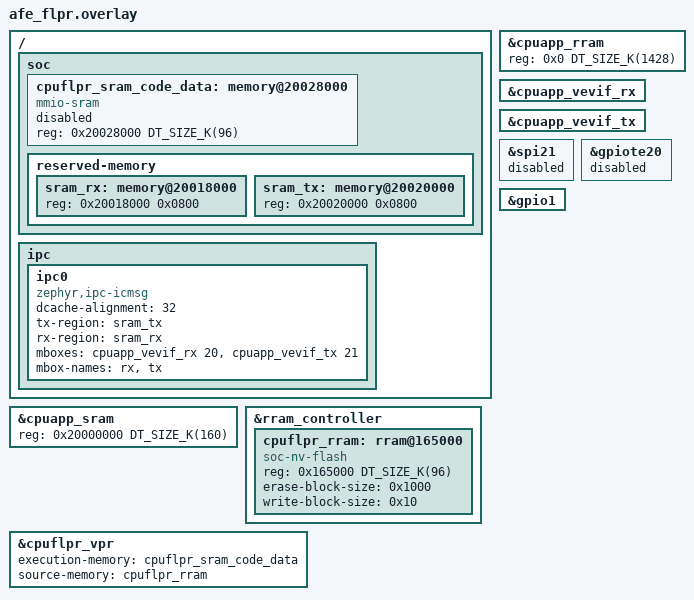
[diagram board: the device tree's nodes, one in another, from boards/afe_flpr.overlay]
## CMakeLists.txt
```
cmake_minimum_required(VERSION 3.20.0)

list(APPEND ZEPHYR_EXTRA_MODULES ${CMAKE_CURRENT_SOURCE_DIR}/../wheeze)

# Where the ADS1292R is read: "flpr" (default) = the RISC-V coprocessor, built
# by sysbuild from flpr/; "app" = an afe thread on this core (no sysbuild needed).
set(AFE_CORE flpr CACHE STRING "Core that reads the ADS1292R: flpr or app")
if(AFE_CORE STREQUAL "flpr")
  list(APPEND EXTRA_DTC_OVERLAY_FILE ${CMAKE_CURRENT_SOURCE_DIR}/boards/afe_flpr.overlay)
elseif(NOT AFE_CORE STREQUAL "app")
  message(FATAL_ERROR "AFE_CORE must be flpr or app")
endif()

find_package(Zephyr REQUIRED HINTS $ENV{ZEPHYR_BASE})
project(anaphylaxis_monitor LANGUAGES C CXX)

target_include_directories(app PRIVATE src)
target_sources(app PRIVATE
  src/main.cpp
  src/afe_link.cpp
  src/burst.cpp
  src/patch_link.cpp
  src/algo/anaphylaxis.cpp
  src/algo/body_motion.cpp
  src/algo/ecg_qrs.cpp
  src/algo/ppg.cpp
  src/algo/resp_rate.cpp
  src/drivers/ads1292r.cpp
  src/drivers/alert.cpp
  src/drivers/lsm6dso.cpp
  src/drivers/max30101.cpp
)
```

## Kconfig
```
# EpiPatch chest patch -- application options.
# All thresholds are PLACEHOLDERS to be set from clinical validation.
# The countdown, release and histamine options live in ../thigh/Kconfig.

menu "EpiPatch chest patch"

config APP_AFE_ON_FLPR
	def_bool $(dt_nodelabel_enabled,cpuflpr_vpr)
	select IPC_SERVICE
	select MBOX
	help
	  The ADS1292R is read by the FLPR coprocessor (flpr/), which runs the
	  heart-rate and breathing triggers and wakes this core only when one
	  fires. Set by the build: on unless CMake is given -DAFE_CORE=app.

config APP_AFE_STACK_SIZE
	int "ECG/Bio-Z thread stack size (AFE on this core only)"
	default 2048

config APP_AFE_THREAD_PRIORITY
	int "ECG/Bio-Z thread priority (must beat main: ADS1292R has no FIFO)"
	default 1

config APP_WATCHDOG_MS
	int "Hardware watchdog timeout [ms]"
	default 4000

menu "Sampling schedule and ECG/Bio-Z triggers"

config APP_SPOT_PERIOD_S
	int "Read all sensors every [s]"
	default 120

config APP_SPOT_WINDOW_S
	int "...for [s] (PPG, mic and histamine on, decision every second)"
	default 15

config APP_BURST_S
	int "After an ECG/Bio-Z trigger, record everything for [s], then analyse"
	range 10 60
	default 60

config APP_TRIG_HR_HIGH_BPM
	int "Heart-rate trigger: at or above [/min]"
	default 110
	help
	  Starts a recording; it is not a finding. Set below the tachycardia
	  finding (APP_HR_HIGH_BPM) so the recording is already running when
	  the finding could form.

config APP_TRIG_HR_LOW_BPM
	int "Heart-rate trigger: at or below [/min]"
	default 40

config APP_TRIG_RR_HIGH_BPM
	int "Breathing trigger: at or above [/min]"
	default 25
	help
	  25/min is where NEWS2 scores breathing rate 3.

config APP_TRIG_RR_LOW_BPM
	int "Breathing trigger: at or below [/min]"
	default 8

config APP_TRIG_APNEA
	bool "Breathing trigger: also on apnea"
	default y

config APP_TRIG_CONFIRM_S
	int "A trigger condition must last [s]"
	default 5

config APP_IMU_FIFO_WTM
	int "IMU FIFO watermark interrupt [samples at 12.5 Hz]"
	range 8 60
	default 32
	help
	  Wakes this core to update posture and collapse detection while the
	  schedule is idle (32 samples = every 2.6 s).

config APP_HIST_PERIOD_S
	int "While reading, ask the thigh patch for fresh histamine every [s]"
	default 10

endmenu

menu "Link to the thigh patch"

config APP_THIGH_FRESH_S
	int "Thigh data counts as missing after [s] without a report"
	default 300
	help
	  Without fresh thigh data the chest has no histamine (no exposure
	  finding) and no thigh fall; it keeps deciding on its own sensors.
	  The thigh reports at least every 2 minutes and on every request.

endmenu

menu "PPG (MAX30101)"

config APP_PPG_RED_PA
	int "Red LED current [0.2 mA steps]"
	range 0 255
	default 36

config APP_PPG_IR_PA
	int "IR LED current [0.2 mA steps]"
	range 0 255
	default 36

endmenu

menu "Chest IMU (LSM6DSO)"

config APP_TAP_ODR_HZ
	int "Accelerometer rate [Hz] (ST recommends >= 417 for taps)"
	default 417

config APP_TAP_THRESHOLD_MG
	int "Tap threshold [mg] (250 mg steps)"
	default 1500

config APP_TAP_COUNT
	int "Taps that cancel a deployment (sent to the thigh patch)"
	range 2 8
	default 3

config APP_TAP_WINDOW_MS
	int "All taps within [ms]"
	default 1500

config APP_IMPACT_MG
	int "Impact (wake-up) threshold [mg] (125 mg steps, max 7875)"
	default 2500

config APP_FREEFALL_MG
	int "Free-fall threshold [mg] (156..500)"
	default 312

config APP_FREEFALL_MS
	int "Free-fall minimum duration [ms]"
	default 60

config APP_CHEST_UP_AXIS
	int "Chest IMU axis pointing to the head when standing (0 +X,1 -X,2 +Y,3 -Y,4 +Z,5 -Z)"
	range 0 5
	default 0

config APP_COLLAPSE_TRANSITION_MS
	int "Collapse: trunk tilt 35 -> 60 deg faster than [ms]"
	default 800
	help
	  A faint crosses this band in ~0.2-0.5 s; lying down on purpose,
	  even briskly, takes about 1 s or more.

config APP_COLLAPSE_STILL_S
	int "Collapse: then motionless for [s]"
	default 15

config APP_FALL_CONFIRM_S
	int "Fall: still lying this long after the impact [s]"
	default 10

config APP_STILL_MG
	int "Motionless / at rest below [mg] of dynamic acceleration"
	default 50

config APP_ACTIVE_MG
	int "Moving above [mg]: ignore heart/breathing-rate findings (exercise)"
	default 150

endmenu

menu "Findings and rules"

config APP_WHEEZE_MIN_S
	int "Wheeze finding: wheeze heard in at least this many seconds..."
	range 1 8
	default 3
	help
	  A single detection is not a finding: the wheeze CNN flags about a
	  quarter of normal breath cycles (0.75 specificity on ICBHI).

config APP_WHEEZE_WINDOW_S
	int "...within this window [s]"
	default 60

config APP_WHEEZE_RECENT_S
	int "Wheeze finding holds for [s] after the repeat rule was last met"
	default 60

config APP_RR_HIGH_BPM
	int "Fast breathing at or above [/min]"
	default 28

config APP_RR_HIGH_HOLD_S
	int "...for [s]"
	default 30

config APP_RR_LOW_BPM
	int "Slow breathing at or below [/min]"
	default 8

config APP_RR_LOW_HOLD_S
	int "...for [s]"
	default 15

config APP_APNEA_S
	int "Apnea: no breath for [s]"
	default 20

config APP_HR_HIGH_BPM
	int "Tachycardia at or above [/min]"
	default 120

config APP_HR_RISE_BPM
	int "...and at least this far above the resting baseline [/min]"
	default 40

config APP_HR_HOLD_S
	int "...for [s]"
	default 60

config APP_PI_DROP_PCT
	int "Perfusion drop: PI at or below this % of baseline"
	default 50

config APP_PI_HOLD_S
	int "...for [s]"
	default 30

config APP_HIST_EXPOSURE_MIN
	int "Elevated histamine (from the thigh) counts as exposure for [min]"
	default 60
	help
	  Plasma histamine peaks 5-10 min after exposure and is back to
	  baseline by 15-60 min (Schwartz 1989), while food reactions reach
	  the airway or circulation in about 30 min (Pumphrey 2000).

config APP_RULE_EXPOSURE
	bool "Rule A: histamine AND (respiratory OR cardiovascular finding)"
	default y

config APP_RULE_RESP_COLLAPSE
	bool "Rule B: respiratory finding AND collapse/fall (no histamine needed)"
	default y

endmenu

module = APP
module-str = app
source "subsys/logging/Kconfig.template.log_config"

endmenu

source "Kconfig.zephyr"
```

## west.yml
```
manifest:
  remotes:
    - name: zephyrproject-rtos
      url-base: https://github.com/zephyrproject-rtos
  projects:
    - name: zephyr
      remote: zephyrproject-rtos
      revision: v4.4.2
      import:
        name-allowlist:
          - cmsis
          - cmsis_6
          - cmsis-dsp
          - cmsis-nn
          - hal_nordic
          - segger
          - mbedtls
          - tf-psa-crypto
  self:
    path: manifest
```

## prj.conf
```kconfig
# EpiPatch chest patch. Battery build: no UART, no logging.
# Use debug.conf for logs over RTT.

CONFIG_CPP=y
CONFIG_STD_CPP20=y
CONFIG_REQUIRES_FULL_LIBCPP=y
CONFIG_FPU=y
CONFIG_FPU_SHARING=y

# microphone wheeze detector (../wheeze module)
CONFIG_WHEEZE_DETECTOR=y

# vital-sign filters (biquads on the FPU)
CONFIG_CMSIS_DSP=y
CONFIG_CMSIS_DSP_FILTERING=y

CONFIG_GPIO=y
CONFIG_SPI=y
CONFIG_I2C=y
CONFIG_WATCHDOG=y
CONFIG_EVENTS=y
# own register-level drivers; keep Zephyr's sensor drivers out
CONFIG_SENSOR=n

CONFIG_MAIN_STACK_SIZE=4096
CONFIG_MAIN_THREAD_PRIORITY=4
CONFIG_PM_DEVICE=y

# Bluetooth LE link to the thigh patch: central + GATT client, one bonded
# peer, LE Secure Connections only, bond kept in RRAM
CONFIG_BT=y
CONFIG_BT_CENTRAL=y
CONFIG_BT_GATT_CLIENT=y
CONFIG_BT_GATT_AUTO_DISCOVER_CCC=y
CONFIG_BT_SMP=y
CONFIG_BT_SMP_SC_ONLY=y
CONFIG_BT_SMP_APP_PAIRING_ACCEPT=y
CONFIG_BT_BONDABLE=y
CONFIG_BT_MAX_CONN=1
CONFIG_BT_MAX_PAIRED=1
CONFIG_BT_SETTINGS=y
CONFIG_BT_DEVICE_NAME="EpiPatch-C"

# Bluetooth bond in RRAM
CONFIG_FLASH=y
CONFIG_FLASH_MAP=y
CONFIG_ZMS=y
CONFIG_SETTINGS=y
CONFIG_SETTINGS_ZMS=y

CONFIG_SERIAL=n
CONFIG_CONSOLE=n
CONFIG_UART_CONSOLE=n
CONFIG_LOG=n
CONFIG_PRINTK=n
CONFIG_BOOT_BANNER=n

# The mic listens only when the sampling schedule asks (wheeze_listen()) or
# while a wheeze is going on; its own duty cycle is effectively off.
CONFIG_WHEEZE_DUTY_SLEEP_MS=3600000
```

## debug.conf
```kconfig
# west build ... -- -DEXTRA_CONF_FILE=debug.conf
# Logs over UART. The overlay's pin map uses the DK's VCOM pins, so for logs
# switch to RTT instead (CONFIG_USE_SEGGER_RTT + CONFIG_LOG_BACKEND_RTT) or remap.
CONFIG_SERIAL=y
CONFIG_CONSOLE=y
CONFIG_LOG=y
CONFIG_PRINTK=y
CONFIG_USE_SEGGER_RTT=y
CONFIG_LOG_BACKEND_RTT=y
CONFIG_LOG_BACKEND_UART=n
CONFIG_UART_CONSOLE=n
CONFIG_RTT_CONSOLE=y
CONFIG_APP_LOG_LEVEL_INF=y
CONFIG_WHEEZE_PROFILING=y
```

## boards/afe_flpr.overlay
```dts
/*
 * The ADS1292R belongs to the FLPR coprocessor (firmware in ../flpr, built by
 * sysbuild): the application core gives up SPI21 and GPIOTE20 (DRDY is on
 * port 1), launches the coprocessor and talks to it over one ICMsg endpoint.
 * Memory layout as in Zephyr's nordic-flpr snippet: the coprocessor runs from
 * the top 96 kB of RAM, so the application core keeps 160 kB.
 */

/ {
	soc {
		cpuflpr_sram_code_data: memory@20028000 {
			compatible = "mmio-sram";
			reg = <0x20028000 DT_SIZE_K(96)>;
			ranges = <0x0 0x20028000 0x18000>;
			status = "reserved";
			#address-cells = <1>;
			#size-cells = <1>;
		};

		reserved-memory {
			#address-cells = <1>;
			#size-cells = <1>;

			sram_rx: memory@20018000 {
				reg = <0x20018000 0x0800>;
			};

			sram_tx: memory@20020000 {
				reg = <0x20020000 0x0800>;
			};
		};
	};

	ipc {
		ipc0: ipc0 {
			compatible = "zephyr,ipc-icmsg";
			dcache-alignment = <32>;
			tx-region = <&sram_tx>;
			rx-region = <&sram_rx>;
			mboxes = <&cpuapp_vevif_rx 20>, <&cpuapp_vevif_tx 21>;
			mbox-names = "rx", "tx";
			status = "okay";
		};
	};
};

&cpuapp_sram {
	reg = <0x20000000 DT_SIZE_K(160)>;
	ranges = <0x0 0x20000000 0x28000>;
};

&cpuapp_rram {
	reg = <0x0 DT_SIZE_K(1428)>;
	ranges = <0x0 0x0 DT_SIZE_K(1428)>;

	/delete-node/ partitions;
};

&rram_controller {
	cpuflpr_rram: rram@165000 {
		compatible = "soc-nv-flash";
		reg = <0x165000 DT_SIZE_K(96)>;
		ranges = <0x0 0x165000 DT_SIZE_K(96)>;
		erase-block-size = <0x1000>;
		write-block-size = <0x10>;
		#address-cells = <1>;
		#size-cells = <1>;
	};
};

&cpuflpr_vpr {
	status = "okay";
	execution-memory = <&cpuflpr_sram_code_data>;
	source-memory = <&cpuflpr_rram>;
};

&cpuapp_vevif_rx {
	status = "okay";
};

&cpuapp_vevif_tx {
	status = "okay";
};

&spi21 {
	status = "disabled";
};

&gpiote20 {
	status = "disabled";
};

/* port 1 pins stay usable here as outputs (motor gate, buzzer), no interrupts */
&gpio1 {
	/delete-property/ gpiote-instance;
};

#define WITH_FLPR_PARTITIONS
#include <vendor/nordic/nrf54l15_cpuapp_partition.dtsi>
```

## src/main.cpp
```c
// EpiPatch chest patch, nRF54L15: senses, analyses and decides.
//
// Who does what
//   FLPR    (low-power RISC-V core, flpr/) ADS1292R at 125 Hz -> heart rate,
//           breathing rate and the two vital-sign triggers. It wakes the main
//           core only when a trigger fires. (With -DAFE_CORE=app an afe thread
//           on the main core does the same; see afe_link.cpp.)
//   main    (Arm Cortex-M33, prio 4) event loop: chest IMU interrupts at any
//           time (tap / impact / free-fall / FIFO watermark), the sampling
//           schedule, the analysis and the decision
//   wheeze  (prio 5) PDM mic -> wheeze CNN (wheeze module), listening when asked
//   BT      Bluetooth LE link to the thigh patch (patch_link.cpp)
//
// The thigh patch (../thigh) owns the histamine sensor, its own fall
// detection, the vibration motor and the release motor. It reports its data
// here; the chest folds it into the decision and sends the verdict back. The
// thigh then runs the countdown, the tap cancel and the release itself.
//
// Sampling schedule (algo/sampling_schedule.hpp)
//   every 2 min      spot read: PPG, mic and thigh histamine for 15 s, decision every second
//   ECG/Bio-Z trigger burst: everything on for 1 min, every sample kept, then
//                    the whole minute is analysed (burst.hpp)
//   countdown on     everything on, decision every second, until it is over
#include <algorithm>
#include <array>
#include <atomic>
#include <cstdint>
#include <span>

#include <zephyr/drivers/watchdog.h>
#include <zephyr/kernel.h>
#include <zephyr/logging/log.h>
#include <zephyr/spinlock.h>

#include <wheeze/wheeze.h>

#include "afe_link.hpp"
#include "algo/anaphylaxis.hpp"
#include "algo/body_motion.hpp"
#include "algo/ppg.hpp"
#include "algo/sampling_schedule.hpp"
#include "algo/tap_counter.hpp"
#include "algo/thigh_view.hpp"
#include "algo/vital_trigger.hpp"
#include "board.hpp"
#include "burst.hpp"
#include "drivers/alert.hpp"
#include "drivers/lsm6dso.hpp"
#include "drivers/max30101.hpp"
#include "patch_link.hpp"

LOG_MODULE_REGISTER(device, CONFIG_APP_LOG_LEVEL);

namespace {

using namespace dev;
using algo::DeployState;
using algo::SamplingSchedule;
using afe_msg::StreamMode;

// ---- events into the main loop ---------------------------------------------

enum : uint32_t {
	kEvPpg = BIT(0),
	kEvChest = BIT(1),
	kEvTrigger = BIT(2),
	kEvReport = BIT(3),
	kEvAll = kEvPpg | kEvChest | kEvTrigger | kEvReport,
};

k_event g_events;

void post(void *bit) { k_event_post(&g_events, static_cast<uint32_t>(reinterpret_cast<uintptr_t>(bit))); }

void *ev_arg(uint32_t bit) { return reinterpret_cast<void *>(static_cast<uintptr_t>(bit)); }

// ---- hardware ----------------------------------------------------------------

// constinit: the compiler guarantees no constructor runs at boot
constinit drv::Max30101 ppg{board::kPpgI2c, board::kPpgInt};
constinit drv::Lsm6dso imu_chest{board::kChestI2c, board::kChestInt};
constinit drv::Alert alert{board::kAlert, board::kStatusLed};

// ---- algorithms --------------------------------------------------------------

// value-initialised ({}), so they are zero-filled at link time instead of
// constructed at boot; each is configured by reset() in configure_algorithms()
constinit algo::PpgProcessor ppg_proc{};
constinit algo::BodyMotion motion{};
constinit algo::TapCounter taps{};
constinit algo::AnaphylaxisEngine engine{};
constinit SamplingSchedule schedule{};
constinit algo::ThighView thigh{};

std::atomic<uint8_t> pending_trigger{0}; // VitalTrigger bits, set by the AFE side

// latest thigh report, written by the Bluetooth thread
constinit k_spinlock report_lock{};
constinit patch_msg::Report pending_report{};
bool report_waiting;

bool ok_ppg, ok_chest;
bool ppg_on;
uint32_t last_ppg_ms, next_hist_ms;
DeployState shown_state = DeployState::Monitoring;

// ---- configuration from Kconfig ----------------------------------------------

algo::Axis axis(int v) { return static_cast<algo::Axis>(std::clamp(v, 0, 5)); }

algo::VitalTrigger::Config trigger_config()
{
	return {
		.hr_high = static_cast<float>(CONFIG_APP_TRIG_HR_HIGH_BPM),
		.hr_low = static_cast<float>(CONFIG_APP_TRIG_HR_LOW_BPM),
		.rr_high = static_cast<float>(CONFIG_APP_TRIG_RR_HIGH_BPM),
		.rr_low = static_cast<float>(CONFIG_APP_TRIG_RR_LOW_BPM),
		.apnea = IS_ENABLED(CONFIG_APP_TRIG_APNEA),
		.confirm_ms = CONFIG_APP_TRIG_CONFIRM_S * 1000u,
	};
}

void configure_algorithms()
{
	ppg_proc.reset({});
	motion.reset({
		.chest_up = axis(CONFIG_APP_CHEST_UP_AXIS),
		.collapse_transition_ms = CONFIG_APP_COLLAPSE_TRANSITION_MS,
		.collapse_still_ms = CONFIG_APP_COLLAPSE_STILL_S * 1000u,
		.fall_confirm_ms = CONFIG_APP_FALL_CONFIRM_S * 1000u,
		.still_g = CONFIG_APP_STILL_MG / 1000.0f,
	});
	taps.reset({.taps = CONFIG_APP_TAP_COUNT, .window_ms = CONFIG_APP_TAP_WINDOW_MS});
	engine.reset({
		.active_g = CONFIG_APP_ACTIVE_MG / 1000.0f,
		.rest_g = CONFIG_APP_STILL_MG / 1000.0f,
		.wheeze_min_s = CONFIG_APP_WHEEZE_MIN_S,
		.wheeze_window_ms = CONFIG_APP_WHEEZE_WINDOW_S * 1000u,
		.wheeze_recent_ms = CONFIG_APP_WHEEZE_RECENT_S * 1000u,
		.rr_high_bpm = static_cast<float>(CONFIG_APP_RR_HIGH_BPM),
		.rr_high_hold_ms = CONFIG_APP_RR_HIGH_HOLD_S * 1000u,
		.rr_low_bpm = static_cast<float>(CONFIG_APP_RR_LOW_BPM),
		.rr_low_hold_ms = CONFIG_APP_RR_LOW_HOLD_S * 1000u,
		.hr_high_bpm = static_cast<float>(CONFIG_APP_HR_HIGH_BPM),
		.hr_rise_bpm = static_cast<float>(CONFIG_APP_HR_RISE_BPM),
		.hr_hold_ms = CONFIG_APP_HR_HOLD_S * 1000u,
		.pi_drop_ratio = CONFIG_APP_PI_DROP_PCT / 100.0f,
		.pi_hold_ms = CONFIG_APP_PI_HOLD_S * 1000u,
		.exposure_hold_ms = CONFIG_APP_HIST_EXPOSURE_MIN * 60000u,
		.rule_exposure = IS_ENABLED(CONFIG_APP_RULE_EXPOSURE),
		.rule_resp_collapse = IS_ENABLED(CONFIG_APP_RULE_RESP_COLLAPSE),
	});
	thigh.reset({.fresh_ms = CONFIG_APP_THIGH_FRESH_S * 1000u});
}

// ---- callbacks (other threads / ISRs) ------------------------------------------

void on_trigger(uint8_t bits)
{
	pending_trigger.fetch_or(bits);
	k_event_post(&g_events, kEvTrigger);
}

void on_report(const patch_msg::Report &r)
{
	const k_spinlock_key_t key = k_spin_lock(&report_lock);
	pending_report = r;
	report_waiting = true;
	k_spin_unlock(&report_lock, key);
	k_event_post(&g_events, kEvReport);
}

// ---- main-loop handlers ----------------------------------------------------------

// the chest's buzzer/LED follow the thigh's countdown
void mirror_thigh_state(DeployState s)
{
	if (s == shown_state) {
		return;
	}
	shown_state = s;
	switch (s) {
	case DeployState::Alert:
		alert.play(drv::Alert::kCountdown, true);
		LOG_WRN("thigh patch: countdown running");
		break;
	case DeployState::Cancelled:
		alert.play(drv::Alert::kCancelAck, true);
		LOG_WRN("thigh patch: cancelled");
		break;
	case DeployState::Deploying:
		LOG_WRN("thigh patch: releasing");
		break;
	case DeployState::Deployed:
		alert.play(drv::Alert::kDeployed, false);
		LOG_WRN("thigh patch: deployed");
		break;
	case DeployState::Fault:
		alert.play(drv::Alert::kFault, true);
		LOG_ERR("thigh patch: release motor fault");
		break;
	case DeployState::Monitoring:
		alert.play(drv::Alert::kOff, false);
		break;
	}
}

void apply_report(uint32_t now)
{
	patch_msg::Report r;
	{
		const k_spinlock_key_t key = k_spin_lock(&report_lock);
		if (!report_waiting) {
			k_spin_unlock(&report_lock, key);
			return;
		}
		r = pending_report;
		report_waiting = false;
		k_spin_unlock(&report_lock, key);
	}
	thigh.on_report(r, now);
	mirror_thigh_state(thigh.state());
}

bool alerting(uint32_t now) { return thigh.alerting(now); }

// the verdict goes to the thigh, which runs the countdown and release
void decide(const algo::Assessment &a)
{
	link::send_decision(a);
	if (a.trigger) {
		LOG_WRN("DECISION: findings 0x%03x%s -> thigh patch", a.findings, a.severe ? " (severe)" : "");
	}
}

void read_imu_fifo(uint32_t now)
{
	std::array<algo::Vec3, drv::Lsm6dso::kMaxFifo> buf;
	const int n = imu_chest.read_fifo(buf);
	if (n <= 0) {
		return;
	}
	const auto s = std::span(buf).first(static_cast<std::size_t>(n));
	// posture and collapse always run live, so they work between scheduled reads
	motion.chest(s, now, drv::Lsm6dso::kFifoDtMs);
	if (schedule.mode() == SamplingSchedule::Mode::Burst) {
		burst::add_imu(true, s);
	}
}

void handle_imu(uint32_t now)
{
	for (int i = 0; i < 4; ++i) {
		const int ev = imu_chest.events();
		if (ev < 0) {
			return;
		}
		if ((ev & drv::Lsm6dso::kTap) && taps.on_tap(now)) {
			link::send_cancel(); // the thigh runs the countdown
			LOG_WRN("cancel tapped on the chest");
		}
		if (ev & drv::Lsm6dso::kImpact) {
			motion.impact(now);
		}
		if (ev & drv::Lsm6dso::kFreeFall) {
			motion.freefall(now);
		}
		if (ev & drv::Lsm6dso::kFifo) {
			read_imu_fifo(now);
		}
		if (!imu_chest.irq_active()) {
			return;
		}
	}
}

void read_ppg(uint32_t now)
{
	std::array<uint32_t, drv::Max30101::kFifoDepth> red, ir;
	const int n = ppg.read(red, ir);
	if (n > 0) {
		const auto cnt = static_cast<std::size_t>(n);
		const auto r = std::span(red).first(cnt);
		const auto i = std::span(ir).first(cnt);
		if (schedule.mode() == SamplingSchedule::Mode::Burst) {
			burst::add_ppg(r, i); // analysed at the end of the minute
		} else {
			ppg_proc.process(r, i);
		}
	}
	last_ppg_ms = now;
}

// histamine is measured on the thigh: ask for a fresh reading
void request_histamine(uint32_t now)
{
	link::request_report();
	next_hist_ms = now + CONFIG_APP_HIST_PERIOD_S * 1000u;
}

// PPG and mic on for listen_ms (0 = until sensors_off(), renewed by tick)
void sensors_on(uint32_t now, uint32_t listen_ms)
{
	if (ok_ppg && !ppg_on) {
		ppg_on = ppg.wake() == 0;
		ppg_proc.reset({});
		last_ppg_ms = now;
	}
	wheeze_listen(listen_ms ? listen_ms : 3000);
	request_histamine(now);
}

void sensors_off()
{
	if (ppg_on) {
		ppg.shutdown();
		ppg_on = false;
	}
	afe::stream(StreamMode::Off);
}

Vitals snapshot(uint32_t now)
{
	const afe::Reading r = afe::latest();
	const bool afe_fresh = r.updated_ms != 0 && now - r.updated_ms < 2000;

	wheeze_stats ws{};
	wheeze_get_stats(&ws);

	Vitals v{};
	v.hr_valid = afe_fresh && r.hr_valid;
	v.hr_bpm = r.hr_bpm;
	v.ecg_leads_off = r.leads_off;
	v.rr_valid = afe_fresh && r.rr_valid;
	v.rr_bpm = r.rr_bpm;
	v.apnea = afe_fresh && r.apnea;
	v.ppg_valid = ppg_on && ppg_proc.valid();
	v.pi_pct = ppg_proc.pi_pct();
	v.pulse_bpm = ppg_proc.pulse_bpm();
	v.spo2_est = ppg_proc.spo2_est();
	v.wheezing = ws.wheezing;
	v.wheeze_events = ws.events;
	v.posture = motion.posture();
	v.activity_g = motion.activity_g();
	v.collapsed = motion.collapsed();
	v.fall = motion.fall();
	thigh.merge(v, now); // histamine, thigh fall and activity
	return v;
}

void log_vitals(const Vitals &v, uint16_t findings)
{
	LOG_INF("HR %s%d RR %s%d PI %d.%02d%% post %d act %dmg hist %s%d/%d nM wz %d find 0x%03x "
		"thigh %d mode %d",
		v.hr_valid ? "" : "~", static_cast<int>(v.hr_bpm), v.rr_valid ? "" : "~",
		static_cast<int>(v.rr_bpm), static_cast<int>(v.pi_pct), static_cast<int>(v.pi_pct * 100) % 100,
		static_cast<int>(v.posture), static_cast<int>(v.activity_g * 1000), v.hist_valid ? "" : "~",
		static_cast<int>(v.hist_nm), static_cast<int>(v.hist_baseline_nm), v.wheezing, findings,
		static_cast<int>(shown_state), static_cast<int>(schedule.mode()));
}

// once a second while the schedule is awake (spot, burst or countdown)
void tick(uint32_t now)
{
	if (ok_chest) {
		read_imu_fifo(now);
	}
	if (ppg_on && now - last_ppg_ms > 2000) {
		read_ppg(now); // missed interrupt: poll
	}
	if (static_cast<int32_t>(now - next_hist_ms) >= 0) {
		request_histamine(now);
	}
	motion.update(now);
	const Vitals v = snapshot(now);

	if (schedule.mode() == SamplingSchedule::Mode::Burst) {
		burst::add_second(v, now); // decided at the end of the minute
		return;
	}
	if (schedule.mode() == SamplingSchedule::Mode::Active) {
		wheeze_listen(3000); // keep the mic on until the countdown is over
	}
	const algo::Assessment a = engine.update(v, now);
	decide(a);

	static uint32_t log_div;
	if (++log_div >= 5) {
		log_div = 0;
		log_vitals(v, a.findings);
	}
}

void end_burst()
{
	const burst::Info info = burst::info();
	const algo::Assessment a = burst::analyse(engine, ppg_proc);
	const afe::Recording rec = afe::recording();
	LOG_INF("burst analysed: %u s, %u PPG, %u IMU, %u ECG/Bio-Z samples; findings 0x%03x%s",
		static_cast<unsigned>(info.seconds), static_cast<unsigned>(info.ppg_samples),
		static_cast<unsigned>(info.chest_samples), static_cast<unsigned>(rec.samples), a.findings,
		a.trigger ? " -> TRIGGER" : "");
	decide(a);
	afe::rearm();
}

void handle_schedule(SamplingSchedule::Action act, uint32_t now)
{
	using A = SamplingSchedule::Action;
	switch (act) {
	case A::StartSpot:
		sensors_on(now, CONFIG_APP_SPOT_WINDOW_S * 1000u);
		afe::stream(StreamMode::Status);
		break;
	case A::StartBurst:
		burst::begin(now);
		sensors_on(now, CONFIG_APP_BURST_S * 1000u);
		afe::stream(StreamMode::Record);
		break;
	case A::StartActive:
		sensors_on(now, 0);
		afe::stream(StreamMode::Status);
		break;
	case A::EndSpot:
		sensors_off();
		break;
	case A::EndActive:
		sensors_off();
		afe::rearm();
		break;
	case A::EndBurst:
		sensors_off();
		end_burst();
		break;
	case A::None:
		break;
	}
}

// ---- boot helpers ------------------------------------------------------------------

struct Watchdog {
	const device *dev = nullptr;
	int channel = -1;

	void start()
	{
#if DT_NODE_HAS_STATUS(DT_ALIAS(watchdog0), okay)
		dev = DEVICE_DT_GET(DT_ALIAS(watchdog0));
		if (!device_is_ready(dev)) {
			dev = nullptr;
			return;
		}
		wdt_timeout_cfg cfg{};
		cfg.window.min = 0;
		cfg.window.max = CONFIG_APP_WATCHDOG_MS;
		cfg.flags = WDT_FLAG_RESET_SOC;
		channel = wdt_install_timeout(dev, &cfg);
		if (channel < 0 || wdt_setup(dev, WDT_OPT_PAUSE_HALTED_BY_DBG) != 0) {
			dev = nullptr;
		}
#endif
	}
	void feed()
	{
		if (dev) {
			wdt_feed(dev, channel);
		}
	}
};

drv::Lsm6dso::Config imu_config()
{
	return {
		.odr_hz = static_cast<uint16_t>(CONFIG_APP_TAP_ODR_HZ),
		.low_power = false,
		.tap = true,
		.tap_mg = CONFIG_APP_TAP_THRESHOLD_MG,
		.impact_mg = CONFIG_APP_IMPACT_MG,
		.freefall_mg = CONFIG_APP_FREEFALL_MG,
		.freefall_ms = CONFIG_APP_FREEFALL_MS,
		.fifo_wtm = CONFIG_APP_IMU_FIFO_WTM,
	};
}

} // namespace

int main()
{
	k_event_init(&g_events);
	alert.init();
	configure_algorithms();

	const int afe_err = afe::start(trigger_config(), CONFIG_APP_APNEA_S * 1000u, on_trigger);
	ok_ppg = ppg.init(CONFIG_APP_PPG_RED_PA, CONFIG_APP_PPG_IR_PA, post, ev_arg(kEvPpg)) == 0;
	if (ok_ppg) {
		ppg.shutdown(); // until the first scheduled read
	}
	ok_chest = imu_chest.init(imu_config(), post, ev_arg(kEvChest)) == 0;
	const int bt_err = link::start(on_report);
	LOG_INF("chest: ecg/bioz %d (%s) ppg %d imu %d bluetooth %d", afe_err == 0,
		IS_ENABLED(CONFIG_APP_AFE_ON_FLPR) ? "FLPR" : "app core", ok_ppg, ok_chest, bt_err == 0);

	const int werr = wheeze_start(nullptr, nullptr);
	if (werr) {
		LOG_ERR("wheeze detector not started (%d)", werr);
	}

	Watchdog wdt;
	wdt.start();

	uint32_t now = k_uptime_get_32();
	schedule.reset(
		{
			.period_ms = CONFIG_APP_SPOT_PERIOD_S * 1000u,
			.spot_ms = CONFIG_APP_SPOT_WINDOW_S * 1000u,
			.burst_ms = CONFIG_APP_BURST_S * 1000u,
		},
		now);
	next_hist_ms = now;
	uint32_t next_tick = now + 1000;

	for (;;) {
		// sleep until an interrupt, the next tick (when awake) or the next
		// scheduled read (when idle); wake at least twice per watchdog period
		now = k_uptime_get_32();
		uint32_t wait = CONFIG_APP_WATCHDOG_MS / 2;
		if (schedule.awake()) {
			const auto to_tick = static_cast<int32_t>(next_tick - now);
			wait = std::min<uint32_t>(wait, to_tick > 0 ? static_cast<uint32_t>(to_tick) : 0);
		} else {
			wait = std::min(wait, schedule.idle_wait_ms(now));
		}
		const uint32_t ev = k_event_wait(&g_events, kEvAll, false, K_MSEC(wait));
		k_event_clear(&g_events, ev);
		now = k_uptime_get_32();

		if (ev & kEvChest) {
			handle_imu(now);
		}
		if ((ev & kEvPpg) && ppg_on) {
			read_ppg(now);
		}
		if (ev & kEvReport) {
			apply_report(now);
		}
		if (ev & kEvTrigger) {
			const uint8_t bits = pending_trigger.exchange(0);
			const auto act = schedule.trigger(now);
			LOG_INF("ECG/Bio-Z trigger 0x%02x%s", bits,
				act == SamplingSchedule::Action::StartBurst ? ": recording 1 min" : "");
			// otherwise a burst or a countdown already has everything on; the
			// trigger is re-armed when that ends
			if (act == SamplingSchedule::Action::StartBurst) {
				handle_schedule(act, now);
				next_tick = now + 1000;
			}
		}

		const bool was_awake = schedule.awake();
		for (auto act = schedule.update(now, alerting(now)); act != SamplingSchedule::Action::None;
		     act = schedule.update(now, alerting(now))) {
			handle_schedule(act, now);
		}
		if (schedule.awake()) {
			if (!was_awake) {
				next_tick = now + 1000;
			}
			if (static_cast<int32_t>(now - next_tick) >= 0) {
				tick(now);
				next_tick += 1000;
				if (static_cast<int32_t>(now - next_tick) >= 0) {
					next_tick = now + 1000; // fell behind; don't burst
				}
			}
		}
		wdt.feed();
	}
	return 0;
}
```

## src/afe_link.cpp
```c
#include "afe_link.hpp"

#include <array>
#include <atomic>
#include <cstring>

#include <zephyr/kernel.h>
#include <zephyr/logging/log.h>
#include <zephyr/spinlock.h>

#if defined(CONFIG_APP_AFE_ON_FLPR)
#include <zephyr/ipc/ipc_service.h>
#else
#include "algo/ecg_qrs.hpp"
#include "algo/resp_rate.hpp"
#include "board.hpp"
#include "drivers/ads1292r.hpp"
#endif

LOG_MODULE_REGISTER(afe, CONFIG_APP_LOG_LEVEL);

namespace dev::afe {
namespace {

namespace msg = dev::afe_msg;

constinit k_spinlock lock{};
constinit Reading last{};
constinit Recording rec{};
TriggerFn on_trigger_fn;

void publish(const Reading &r)
{
	const k_spinlock_key_t key = k_spin_lock(&lock);
	last = r;
	k_spin_unlock(&lock, key);
}

} // namespace

Reading latest()
{
	const k_spinlock_key_t key = k_spin_lock(&lock);
	const Reading r = last;
	k_spin_unlock(&lock, key);
	return r;
}

Recording recording()
{
	const k_spinlock_key_t key = k_spin_lock(&lock);
	const Recording r = rec;
	k_spin_unlock(&lock, key);
	return r;
}

#if defined(CONFIG_APP_AFE_ON_FLPR)

// ---- the FLPR coprocessor reads the ADS1292R; we talk to it over IPC ----------

namespace {

ipc_ept ep;
std::atomic<bool> bound{false};
msg::Config config_msg;
k_work send_config_work;

void send_config(k_work *) { ipc_service_send(&ep, &config_msg, sizeof(config_msg)); }

void on_bound(void *)
{
	bound = true;
	k_work_submit(&send_config_work); // not from inside the IPC callback
	LOG_INF("AFE coprocessor linked");
}

void on_received(const void *data, size_t len, void *)
{
	if (len < 1) {
		return;
	}
	switch (static_cast<msg::Type>(*static_cast<const uint8_t *>(data))) {
	case msg::Type::Trigger:
		if (len == sizeof(msg::Trigger) && on_trigger_fn) {
			on_trigger_fn(static_cast<const msg::Trigger *>(data)->bits);
		}
		break;
	case msg::Type::Status:
		if (len == sizeof(msg::Status)) {
			const auto *s = static_cast<const msg::Status *>(data);
			publish({
				.hr_valid = (s->flags & msg::kHrValid) != 0,
				.hr_bpm = s->hr_bpm,
				.leads_off = (s->flags & msg::kLeadsOff) != 0,
				.rr_valid = (s->flags & msg::kRrValid) != 0,
				.rr_bpm = s->rr_bpm,
				.apnea = (s->flags & msg::kApnea) != 0,
				.updated_ms = k_uptime_get_32(),
			});
		}
		break;
	case msg::Type::Recording:
		if (len == sizeof(msg::Recording)) {
			const auto *r = static_cast<const msg::Recording *>(data);
			const k_spinlock_key_t key = k_spin_lock(&lock);
			// the coprocessor's RAM is part of the same address space
			rec = {reinterpret_cast<const uint8_t *>(static_cast<uintptr_t>(r->addr)), r->samples,
			       r->sps};
			k_spin_unlock(&lock, key);
		}
		break;
	default:
		break;
	}
}

template <typename T> void send(const T &m)
{
	if (bound) {
		ipc_service_send(&ep, &m, sizeof(m));
	}
}

} // namespace

int start(const algo::VitalTrigger::Config &trig, uint32_t apnea_ms, TriggerFn on_trigger)
{
	on_trigger_fn = on_trigger;
	config_msg = {
		.type = msg::Type::Config,
		.trig_apnea = trig.apnea,
		.reserved = {},
		.hr_high = trig.hr_high,
		.hr_low = trig.hr_low,
		.rr_high = trig.rr_high,
		.rr_low = trig.rr_low,
		.confirm_ms = trig.confirm_ms,
		.apnea_ms = apnea_ms,
	};
	k_work_init(&send_config_work, send_config);

	static const ipc_ept_cfg cfg = {
		.name = "afe",
		.cb = {.bound = on_bound, .received = on_received},
	};
	const device *ipc = DEVICE_DT_GET(DT_NODELABEL(ipc0));
	int err = ipc_service_open_instance(ipc);
	if (err && err != -EALREADY) {
		return err;
	}
	return ipc_service_register_endpoint(ipc, &ep, &cfg);
}

void stream(msg::StreamMode mode) { send(msg::Stream{.type = msg::Type::Stream, .mode = mode}); }

void rearm() { send(msg::Rearm{.type = msg::Type::Rearm}); }

#else

// ---- the ADS1292R is read on this core, by the afe thread ---------------------

namespace {

constinit drv::Ads1292r ads{board::kAdsSpi, board::kAdsDrdy, board::kAdsPwdn, board::kAdsStart};
constinit algo::QrsDetector qrs{};
constinit algo::RespRate resp{};
constinit algo::VitalTrigger trig{};

constexpr std::size_t kRecordSamples = CONFIG_APP_BURST_S * drv::Ads1292r::kSps;
constinit uint8_t record_buf[kRecordSamples * 6]{};
std::atomic<uint8_t> mode{static_cast<uint8_t>(msg::StreamMode::Off)};
std::atomic<bool> rearm_pending{false};

K_THREAD_STACK_DEFINE(afe_stack, CONFIG_APP_AFE_STACK_SIZE);
k_thread afe_thread;

void put24(uint8_t *p, int32_t v)
{
	p[0] = static_cast<uint8_t>(v >> 16);
	p[1] = static_cast<uint8_t>(v >> 8);
	p[2] = static_cast<uint8_t>(v);
}

void afe_loop(void *, void *, void *)
{
	constexpr std::size_t kBlock = drv::Ads1292r::kSps / 5; // 200 ms
	std::array<float, kBlock> ecg, bioz;
	std::size_t n = 0, blocks = 0, rec_n = 0;
	uint8_t loff = 0;
	int misses = 0;
	auto last_mode = msg::StreamMode::Off;

	for (;;) {
		if (ads.wait(K_MSEC(100)) != 0) {
			if (++misses >= 10) {
				// no DRDY for a second: restart the AFE
				LOG_WRN("ADS1292R stalled, re-initialising");
				ads.init();
				misses = 0;
			}
			continue;
		}
		misses = 0;
		drv::Ads1292r::Sample s;
		if (ads.read(s) != 0) {
			continue;
		}

		const auto m = static_cast<msg::StreamMode>(mode.load());
		if (m == msg::StreamMode::Record && last_mode != msg::StreamMode::Record) {
			rec_n = 0;
		}
		if (m == msg::StreamMode::Record && rec_n < kRecordSamples) {
			put24(&record_buf[rec_n * 6], s.ecg);
			put24(&record_buf[rec_n * 6 + 3], s.resp);
			if (++rec_n == kRecordSamples) {
				const k_spinlock_key_t key = k_spin_lock(&lock);
				rec = {record_buf, static_cast<uint32_t>(rec_n), drv::Ads1292r::kSps};
				k_spin_unlock(&lock, key);
			}
		}
		last_mode = m;

		ecg[n] = s.ecg * drv::Ads1292r::kEcgUvPerLsb;
		bioz[n] = static_cast<float>(s.resp);
		loff |= s.loff;
		if (++n < kBlock) {
			continue;
		}
		n = 0;
		// breathing is measured through the same two electrodes as the ECG
		const bool off = loff & (drv::Ads1292r::kLoffEcg | drv::Ads1292r::kLoffResp);
		loff = 0;
		qrs.process(ecg, off);
		resp.process(bioz, off);
		const Reading r{
			.hr_valid = qrs.hr_valid(),
			.hr_bpm = qrs.hr_bpm(),
			.leads_off = off,
			.rr_valid = resp.valid(),
			.rr_bpm = resp.rate_bpm(),
			.apnea = resp.apnea(),
			.updated_ms = k_uptime_get_32(),
		};
		publish(r);
		if (++blocks < 5) {
			continue;
		}
		blocks = 0;

		// ---- once a second: the triggers ----
		if (rearm_pending.exchange(false)) {
			trig.rearm();
		}
		const uint8_t fired = trig.update(
			{
				.hr_valid = r.hr_valid,
				.hr_bpm = r.hr_bpm,
				.rr_valid = r.rr_valid,
				.rr_bpm = r.rr_bpm,
				.apnea = r.apnea,
				.leads_off = off,
			},
			r.updated_ms);
		if (fired && on_trigger_fn) {
			on_trigger_fn(fired);
		}
	}
}

} // namespace

int start(const algo::VitalTrigger::Config &cfg, uint32_t apnea_ms, TriggerFn on_trigger)
{
	on_trigger_fn = on_trigger;
	qrs.reset();
	resp.reset({.apnea_ms = apnea_ms});
	trig.reset(cfg);
	const int err = ads.init();
	if (err) {
		return err;
	}
	k_thread_create(&afe_thread, afe_stack, K_THREAD_STACK_SIZEOF(afe_stack), afe_loop, nullptr, nullptr,
			nullptr, CONFIG_APP_AFE_THREAD_PRIORITY, K_FP_REGS, K_NO_WAIT);
	k_thread_name_set(&afe_thread, "afe");
	return 0;
}

void stream(msg::StreamMode m) { mode = static_cast<uint8_t>(m); }

void rearm() { rearm_pending = true; }

#endif

} // namespace dev::afe
```

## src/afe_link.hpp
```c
// The application core's view of the ADS1292R (ECG heart rate, Bio-Z
// breathing) and its two vital-sign triggers, wherever it is read:
//   CONFIG_APP_AFE_ON_FLPR=y  the FLPR coprocessor reads it (flpr/); this file
//                             talks to it over IPC
//   otherwise                 an afe thread on this core reads it
// Either way the trigger callback runs outside the main thread: post an event.
#pragma once

#include <cstdint>

#include "afe_msgs.hpp"
#include "algo/vital_trigger.hpp"

namespace dev::afe {

struct Reading {
	bool hr_valid;
	float hr_bpm;
	bool leads_off;
	bool rr_valid;
	float rr_bpm;
	bool apnea;
	uint32_t updated_ms; // uptime of the reading; 0 = none yet
};

// A completed raw minute: 6 bytes per sample (ECG, Bio-Z; 24-bit big-endian).
struct Recording {
	const uint8_t *data;
	uint32_t samples;
	uint32_t sps;
};

using TriggerFn = void (*)(uint8_t bits); // algo::VitalTrigger::Bits

int start(const algo::VitalTrigger::Config &trig, uint32_t apnea_ms, TriggerFn on_trigger);

// Off: triggers only. Status: a Reading every second. Record: also keep every
// ECG/Bio-Z sample of the next CONFIG_APP_BURST_S seconds.
void stream(afe_msg::StreamMode mode);

// The burst a trigger started has been analysed: let the triggers fire again.
void rearm();

Reading latest();

// Most recent completed recording; samples == 0 if none.
Recording recording();

} // namespace dev::afe
```

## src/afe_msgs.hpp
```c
// Messages between the application core and the FLPR coprocessor that owns
// the ADS1292R (one IPC endpoint, "afe"). Both cores are little-endian 32-bit
// and these structs only hold naturally aligned scalars, so they are sent as
// they are.
//
//   app  -> flpr   Config   trigger thresholds and apnea time (sent at boot)
//                  Stream   Off: triggers only / Status: one Status a second /
//                           Record: Status a second + keep every ECG and
//                           Bio-Z sample of the next minute
//                  Rearm    the burst a trigger started has been analysed
//   flpr -> app    Trigger  a heart-rate or breathing trigger fired
//                  Status   heart rate, breathing rate, apnea, leads-off
//                  Recording where the recorded minute is, once it is complete
#pragma once

#include <cstdint>

namespace dev::afe_msg {

enum class Type : uint8_t { Config = 1, Stream, Rearm, Trigger, Status, Recording };
enum class StreamMode : uint8_t { Off = 0, Status, Record };

enum StatusFlags : uint8_t { kHrValid = 1u << 0, kRrValid = 1u << 1, kApnea = 1u << 2, kLeadsOff = 1u << 3 };

struct Config {
	Type type;
	uint8_t trig_apnea; // bool
	uint8_t reserved[2];
	float hr_high, hr_low, rr_high, rr_low;
	uint32_t confirm_ms;
	uint32_t apnea_ms;
};

struct Stream {
	Type type;
	StreamMode mode;
};

struct Rearm {
	Type type;
};

struct Trigger {
	Type type;
	uint8_t bits; // algo::VitalTrigger::Bits
	uint8_t reserved[2];
	float hr_bpm, rr_bpm;
};

struct Status {
	Type type;
	uint8_t flags; // StatusFlags
	uint8_t reserved[2];
	float hr_bpm, rr_bpm;
};

// The recorded minute stays in the coprocessor's RAM (readable by the
// application core) until the next Record request overwrites it.
// Each sample is 6 bytes: ECG then Bio-Z, 24-bit two's complement, big-endian
// as the ADS1292R delivers them.
struct Recording {
	Type type;
	uint8_t reserved[3];
	uint32_t addr;
	uint32_t samples;
	uint32_t sps;
};

static_assert(sizeof(Config) == 28 && sizeof(Trigger) == 12 && sizeof(Status) == 12 &&
	      sizeof(Recording) == 16);

} // namespace dev::afe_msg
```

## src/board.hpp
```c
// Every devicetree-described part of the chest patch in one place.
// See boards/*.overlay for the wiring; dts/bindings for the properties.
// (The thigh patch has its own: ../../thigh/src/board.hpp.)
#pragma once

#include <zephyr/devicetree.h>
#include <zephyr/drivers/gpio.h>
#include <zephyr/drivers/i2c.h>
#include <zephyr/drivers/spi.h>

namespace dev::board {

#define DEV_ADS_NODE DT_NODELABEL(ads1292r)
#define DEV_PPG_NODE DT_NODELABEL(ppg)
#define DEV_IMU_CHEST_NODE DT_NODELABEL(imu_chest)
#define DEV_USER_NODE DT_PATH(zephyr_user)

#if !DT_NODE_HAS_STATUS(DEV_PPG_NODE, okay) || !DT_NODE_HAS_STATUS(DEV_IMU_CHEST_NODE, okay)
#error "Devicetree needs nodes labelled ppg and imu_chest (see boards/)"
#endif
// The ADS1292R is on this core only when the FLPR coprocessor isn't reading it
#if !defined(CONFIG_APP_AFE_ON_FLPR) && !DT_NODE_HAS_STATUS(DEV_ADS_NODE, okay)
#error "Devicetree needs a node labelled ads1292r (see boards/)"
#endif

#if !defined(CONFIG_APP_AFE_ON_FLPR)
// ADS1292R on SPI mode 1 (CPOL 0, CPHA 1). Two-argument form: Zephyr >= 4.2
// takes CS delays from the devicetree.
inline constexpr spi_dt_spec kAdsSpi =
	SPI_DT_SPEC_GET(DEV_ADS_NODE, SPI_WORD_SET(8) | SPI_TRANSFER_MSB | SPI_MODE_CPHA);
inline constexpr gpio_dt_spec kAdsDrdy = GPIO_DT_SPEC_GET(DEV_ADS_NODE, drdy_gpios);
inline constexpr gpio_dt_spec kAdsPwdn = GPIO_DT_SPEC_GET_OR(DEV_ADS_NODE, pwdn_gpios, {});
inline constexpr gpio_dt_spec kAdsStart = GPIO_DT_SPEC_GET_OR(DEV_ADS_NODE, start_gpios, {});
#endif

inline constexpr i2c_dt_spec kPpgI2c = I2C_DT_SPEC_GET(DEV_PPG_NODE);
inline constexpr gpio_dt_spec kPpgInt = GPIO_DT_SPEC_GET_OR(DEV_PPG_NODE, int_gpios, {});

inline constexpr i2c_dt_spec kChestI2c = I2C_DT_SPEC_GET(DEV_IMU_CHEST_NODE);
inline constexpr gpio_dt_spec kChestInt = GPIO_DT_SPEC_GET(DEV_IMU_CHEST_NODE, int1_gpios);

// buzzer (mirrors the thigh's countdown) and status LED: both optional
inline constexpr gpio_dt_spec kAlert = GPIO_DT_SPEC_GET_OR(DEV_USER_NODE, alert_gpios, {});
inline constexpr gpio_dt_spec kStatusLed = GPIO_DT_SPEC_GET_OR(DEV_USER_NODE, status_led_gpios, {});

} // namespace dev::board
```

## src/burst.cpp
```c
#include "burst.hpp"

#include <algorithm>
#include <array>
#include <cmath>

// Pure C++ (no Zephyr), so the host tests use it too.
#if defined(CONFIG_APP_BURST_S)
#define BURST_S CONFIG_APP_BURST_S
#else
#define BURST_S 60
#endif

namespace dev::burst {
namespace {

constexpr std::size_t kSeconds = BURST_S + 2;           // a little slack for tick jitter
constexpr std::size_t kPpg = (BURST_S + 2) * 25 + 32;   // 25 Hz + one FIFO
constexpr std::size_t kImu = (BURST_S + 2) * 13 + 64;   // 12.5 Hz + one FIFO

struct Second {
	uint32_t t_ms;
	uint32_t ppg_end; // PPG samples received by this second
	Vitals v;
};

// accelerometer samples stored as mg to halve the RAM
struct Mg3 {
	int16_t x, y, z;
};

constinit std::array<Second, kSeconds> seconds{};
constinit std::array<uint32_t, kPpg> red{}, ir{};
constinit std::array<Mg3, kImu> chest{}, thigh{};
constinit std::size_t n_sec{}, n_ppg{}, n_chest{}, n_thigh{};

int16_t to_mg(float g) { return static_cast<int16_t>(std::clamp(std::lround(g * 1000.0f), -32768L, 32767L)); }

} // namespace

void begin(uint32_t)
{
	n_sec = n_ppg = n_chest = n_thigh = 0;
}

void add_ppg(std::span<const uint32_t> r, std::span<const uint32_t> i)
{
	const std::size_t n = std::min({r.size(), i.size(), kPpg - n_ppg});
	std::copy_n(r.begin(), n, red.begin() + n_ppg);
	std::copy_n(i.begin(), n, ir.begin() + n_ppg);
	n_ppg += n;
}

void add_imu(bool is_chest, std::span<const algo::Vec3> s)
{
	auto &buf = is_chest ? chest : thigh;
	auto &cnt = is_chest ? n_chest : n_thigh;
	for (const auto &a : s) {
		if (cnt == kImu) {
			break;
		}
		buf[cnt++] = {to_mg(a.x), to_mg(a.y), to_mg(a.z)};
	}
}

void add_second(const Vitals &v, uint32_t now_ms)
{
	if (n_sec < kSeconds) {
		seconds[n_sec++] = {now_ms, static_cast<uint32_t>(n_ppg), v};
	}
}

Info info() { return {n_sec, n_ppg, n_chest, n_thigh}; }

algo::Assessment analyse(algo::AnaphylaxisEngine &engine, algo::PpgProcessor &ppg_proc)
{
	ppg_proc.reset({});
	algo::Assessment out{};
	uint16_t findings = 0;
	bool trigger = false, severe = false;
	std::size_t fed = 0;
	for (std::size_t i = 0; i < n_sec; ++i) {
		Second &s = seconds[i];
		const std::size_t end = std::min<std::size_t>(s.ppg_end, n_ppg);
		if (end > fed) {
			ppg_proc.process(std::span(red).subspan(fed, end - fed), std::span(ir).subspan(fed, end - fed));
			fed = end;
		}
		s.v.ppg_valid = ppg_proc.valid();
		s.v.pi_pct = ppg_proc.pi_pct();
		s.v.pulse_bpm = ppg_proc.pulse_bpm();
		s.v.spo2_est = ppg_proc.spo2_est();
		out = engine.update(s.v, s.t_ms);
		findings |= out.findings;
		trigger |= out.trigger;
		severe |= out.severe;
	}
	out.findings = findings;
	out.trigger = trigger;
	out.severe = severe;
	return out;
}

} // namespace dev::burst
```

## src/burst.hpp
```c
// One-minute burst recording, started by an ECG/Bio-Z trigger.
//
// While it runs, every PPG and accelerometer sample is kept here, plus a
// snapshot of everything else each second (heart rate and breathing from the
// AFE, wheeze, posture/collapse/fall, histamine). The raw ECG/Bio-Z minute is
// kept where the ADS1292R is read (see afe::recording()). Nothing is decided
// during the minute; analyse() then replays it second by second through the
// PPG processor and the decision engine.
#pragma once

#include <cstddef>
#include <cstdint>
#include <span>

#include "algo/anaphylaxis.hpp"
#include "algo/body_motion.hpp"
#include "algo/ppg.hpp"
#include "algo/vitals.hpp"

namespace dev::burst {

void begin(uint32_t now_ms);

// raw samples as they arrive
void add_ppg(std::span<const uint32_t> red, std::span<const uint32_t> ir);
void add_imu(bool chest, std::span<const algo::Vec3> samples);

// once a second; the PPG fields of v are ignored (they come from the raw PPG)
void add_second(const Vitals &v, uint32_t now_ms);

struct Info {
	std::size_t seconds;
	std::size_t ppg_samples;
	std::size_t chest_samples, thigh_samples;
};
Info info();

// Replays the minute through ppg_proc (reset first) and engine. Returns the
// last second's assessment with trigger/severe/findings OR-ed over the minute.
algo::Assessment analyse(algo::AnaphylaxisEngine &engine, algo::PpgProcessor &ppg_proc);

} // namespace dev::burst
```

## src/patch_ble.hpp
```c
// The Bluetooth LE service that links the two patches. The thigh patch is the
// GATT server (peripheral); the chest patch connects to it (central).
//
//   service      EpiPatch link
//   to-thigh     write without response   patch_msg::Decision / Cancel / ReportNow
//   to-chest     notify                   patch_msg::Report
//
// Both characteristics need an encrypted link. The patches pair once (LE
// Secure Connections, bonded), and each one refuses pairing while it already
// has a bond, so only its partner can ever write a decision. Pairing again
// (for example after replacing a patch) needs the bond erased on both.
#pragma once

#include <zephyr/bluetooth/uuid.h>

#define EPIPATCH_UUID_SVC_VAL BT_UUID_128_ENCODE(0x5e6a0001, 0x7c1d, 0x4c55, 0x9f0e, 0x2b51e2a0d001)
#define EPIPATCH_UUID_TO_THIGH_VAL BT_UUID_128_ENCODE(0x5e6a0002, 0x7c1d, 0x4c55, 0x9f0e, 0x2b51e2a0d001)
#define EPIPATCH_UUID_TO_CHEST_VAL BT_UUID_128_ENCODE(0x5e6a0003, 0x7c1d, 0x4c55, 0x9f0e, 0x2b51e2a0d001)

#define EPIPATCH_UUID_SVC BT_UUID_DECLARE_128(EPIPATCH_UUID_SVC_VAL)
#define EPIPATCH_UUID_TO_THIGH BT_UUID_DECLARE_128(EPIPATCH_UUID_TO_THIGH_VAL)
#define EPIPATCH_UUID_TO_CHEST BT_UUID_DECLARE_128(EPIPATCH_UUID_TO_CHEST_VAL)
```

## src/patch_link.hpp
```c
// Chest side of the Bluetooth LE link to the thigh patch (central, GATT
// client). Connects to the thigh, encrypts the link, subscribes to its
// Reports, and sends the chest's decisions and cancels.
// Callbacks run on the Bluetooth thread: post an event and return.
#pragma once

#include <cstdint>

#include "algo/anaphylaxis.hpp"
#include "patch_msgs.hpp"

namespace dev::link {

using ReportFn = void (*)(const patch_msg::Report &r);

int start(ReportFn on_report);

// encrypted, discovered and subscribed
bool ready();

void send_decision(const algo::Assessment &a);
void send_cancel();
void request_report();

} // namespace dev::link
```

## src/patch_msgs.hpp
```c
// Messages between the chest patch and the thigh patch over their encrypted
// Bluetooth LE link (one GATT service on the thigh patch; see patch_link_*.cpp).
// Both patches are nRF54L15s (little-endian, same compiler), and these structs
// only hold naturally aligned scalars, so they are sent as they are.
//
//   chest -> thigh   Decision    the chest's verdict after each analysis:
//                                trigger / severe (rule A or B), findings
//                    Cancel      three taps on the chest
//                    ReportNow   the chest is starting a reading; send fresh data
//   thigh -> chest   Report      histamine, thigh fall/activity, countdown state
//
// The chest makes every decision. The thigh runs the countdown, the tap
// cancel and the release itself, so a countdown that has started finishes
// (or is cancelled) even if the link drops. With no link the thigh does
// nothing new.
#pragma once

#include <cstdint>

namespace dev::patch_msg {

enum class Type : uint8_t { Decision = 1, Cancel, ReportNow, Report };

struct Decision {
	Type type;
	uint8_t trigger; // bool: rule A or B met
	uint8_t severe;  // bool: respiratory + collapse/fall (re-alerts after a cancel)
	uint8_t reserved;
	uint16_t findings; // algo::Finding bits
	uint16_t reserved2;
	uint32_t seq;
};

struct Cancel {
	Type type;
	uint8_t reserved[3];
	uint32_t seq;
};

struct ReportNow {
	Type type;
	uint8_t reserved[3];
};

enum ReportFlags : uint8_t {
	kHistValid = 1u << 0,
	kHistElevated = 1u << 1,
	kFall = 1u << 2,
	kImuValid = 1u << 3,
};

// algo::DeployState as a byte
struct Report {
	Type type;
	uint8_t flags;       // ReportFlags
	uint8_t deploy_state;
	uint8_t deployments;
	float hist_nm;
	float hist_baseline_nm;
	float activity_g;
	uint32_t seq;
};

static_assert(sizeof(Decision) == 12 && sizeof(Cancel) == 8 && sizeof(ReportNow) == 4 &&
	      sizeof(Report) == 20);

} // namespace dev::patch_msg
```

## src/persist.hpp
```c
#pragma once

#include <cstdint>

namespace dev::persist {

int load(uint8_t &deployments);
int save(uint8_t deployments);

} // namespace dev::persist
```
